# SIM3L168_A register map
File version: 1
CPU: 
Registers are 32-bit, read-write, reset 0x0 unless marked. A register's access mark holds for its fields unless they carry their own. Offsets are from the block's base; [hi:lo] are bit positions; {n}, {i} and the like mark numbered series; <NAME> marks a mode.

## RTC_0
Base 0x40029000
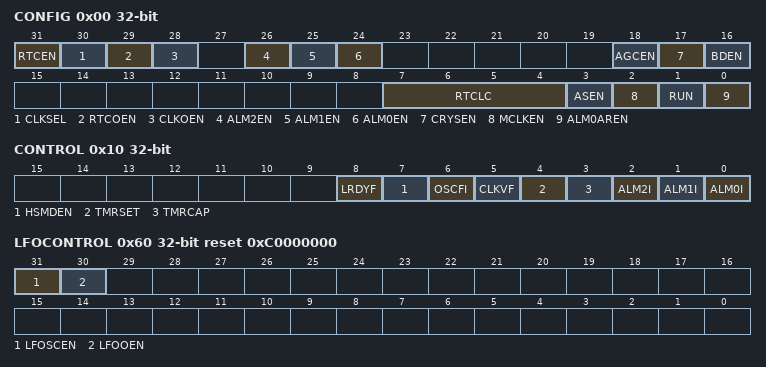
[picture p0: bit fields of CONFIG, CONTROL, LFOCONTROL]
0x00 CONFIG — RTC Configuration
  [31] RTCEN — RTC Timer Enable.
    0=DISABLED (Disable the RTC timer.); 1=ENABLED (Enable the RTC timer.)
  [30] CLKSEL — RTC Timer Clock Select.
    0=RTCNOSC (Select the External Crystal or External CMOS Clock as the RTC Timer clock (RTCnTCLK) source.); 1=LFOSCN (Select the Low Frequency Oscillator as the RTC Timer clock (RTCnTCLK) source.)
  [29] RTCOEN — RTC External Output Enable.
    0=DISABLED (Disable the external RTCnTCLK_OUT output.); 1=ENABLED (Enable the external RTCnTCLK_OUT output.)
  [28] CLKOEN — RTC Clock Output Enable.
    0=DISABLED (Disable the RTCnTCLK output to the timer and other internal modules.); 1=ENABLED (Enable the RTCnTCLK output to the timer and other internal modules.)
  [26] ALM2EN — Alarm 2 Enable.
    0=DISABLED (Disable RTC Alarm 2.); 1=ENABLED (Enable RTC Alarm 2.)
  [25] ALM1EN — Alarm 1 Enable.
    0=DISABLED (Disable RTC Alarm 1.); 1=ENABLED (Enable RTC Alarm 1.)
  [24] ALM0EN — Alarm 0 Enable.
    0=DISABLED (Disable RTC Alarm 0.); 1=ENABLED (Enable RTC Alarm 0.)
  [18] AGCEN — Automatic Gain Control Enable.
    0=DISABLED (Disable automatic gain control.); 1=ENABLED (Enable automatic gain control, saving power.)
  [17] CRYSEN — Crystal Oscillator Enable.
    0=DISABLED (Disable the crystal oscillator circuitry.); 1=ENABLED (Enable the crystal oscillator circuitry.)
  [16] BDEN — Bias Doubler Enable.
    0=DISABLED (Disable the bias doubler, saving power.); 1=ENABLED (Enable the bias doubler.)
  [7:4] RTCLC — Load Capacitance Value.
  [3] ASEN — Automatic Crystal Load Capacitance Stepping Enable.
    0=DISABLED (Disable automatic load capacitance stepping.); 1=ENABLED (Enable automatic load capacitance stepping.)
  [2] MCLKEN — Missing Clock Detector Enable.
    0=DISABLED (Disable the missing clock detector.); 1=ENABLED (Enable the missing clock detector. If the missing clock detector triggers, it will generate an RTC Fail event.)
  [1] RUN — RTC Timer Run Control.
    0=STOP (Stop the RTC timer.); 1=START (Run the RTC timer.)
  [0] ALM0AREN — Alarm 0 Automatic Reset Enable.
    0=DISABLED (Disable the Alarm 0 automatic reset.); 1=ENABLED (Enable the Alarm 0 automatic reset.)
0x10 CONTROL — RTC Control
  [8] LRDYF ro — RTC Load Capacitance Ready Flag.
    0=NOT_SET (The load capacitance is currently stepping.); 1=SET (The load capacitance has reached its programmed value.)
  [7] HSMDEN — RTC High Speed Mode Enable.
    0=DISABLED (Disable high speed mode. (AHBCLK < 4x RTCnTCLK)); 1=ENABLED (Enable high speed mode. (AHBCLK >= 4x RTCnTCLK))
  [6] OSCFI — RTC Oscillator Fail Interrupt Flag.
    0=NOT_SET (Oscillator is running.); 1=SET (Oscillator has failed.)
  [5] CLKVF ro — RTC External Oscillator Valid Flag.
    0=NOT_SET (External oscillator is not valid.); 1=SET (External oscillator is valid.)
  [4] TMRSET — RTC Timer Set.
    0=NOT_SET (RTC timer set operation is complete.); 1=SET (Start the RTC timer set.)
  [3] TMRCAP — RTC Timer Capture.
    0=NOT_SET (RTC timer capture operation is complete.); 1=SET (Start the RTC timer capture.)
  [2] ALM2I — Alarm 2 Interrupt Flag.
    0=NOT_SET (Alarm 2 event has not occurred.); 1=SET (Alarm 2 event occurred.)
  [1] ALM1I — Alarm 1 Interrupt Flag.
    0=NOT_SET (Alarm 1 event has not occurred.); 1=SET (Alarm 1 event occurred.)
  [0] ALM0I — Alarm 0 Interrupt Flag.
    0=NOT_SET (Alarm 0 event has not occurred.); 1=SET (Alarm 0 event occurred.)
{0x20+0x10*i} ALARM{i} (i=0..2) — RTC Alarm {i}
  [31:0] ALARM{i} — RTC Alarm {i}.
0x50 SETCAP — RTC Timer Set/Capture Value
  [31:0] SETCAP — RTC Timer Set/Capture Value.
0x60 LFOCONTROL reset 0xC0000000 — LFOSC Control
  [31] LFOSCEN — Low Frequency Oscillator Enable.
    0=DISABLED (Disable the Low Frequency Oscillator (LFOSCn).); 1=ENABLED (Enable the Low Frequency Oscillator (LFOSCn).)
  [30] LFOOEN — Low Frequency Oscillator Output Enable.
    0=DISABLED (Disable the Low Frequency Oscillator output to internal modules.); 1=ENABLED (Enable the Low Frequency Oscillator output to internal module.)
